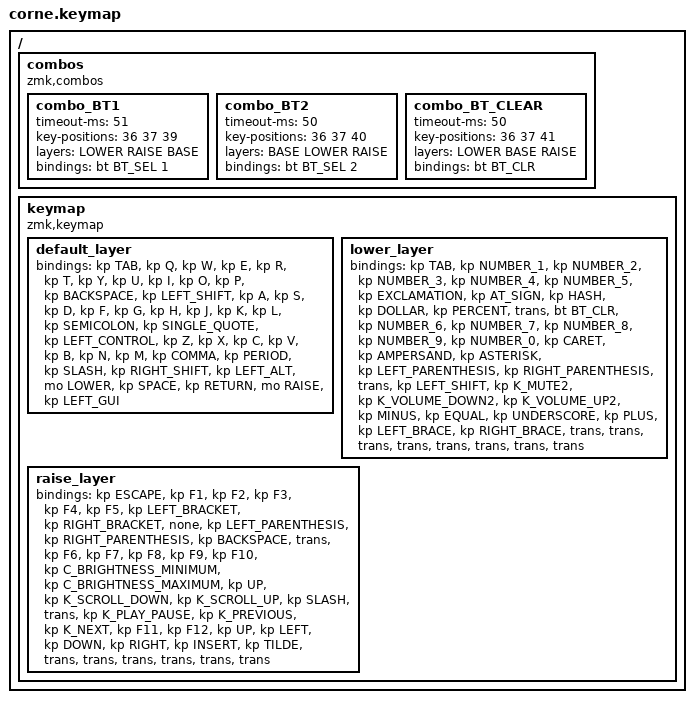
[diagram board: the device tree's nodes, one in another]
#include <behaviors.dtsi>
#include <dt-bindings/zmk/keys.h>
#include <dt-bindings/zmk/bt.h>

#define BASE 0
#define LOWER 1
#define RAISE 2

/ {
  combos {
    compatible = "zmk,combos";
    
    combo_BT1 {
      timeout-ms = <51>;
      key-positions = <36 37 39>;
      layers = <LOWER RAISE BASE>;
      bindings = <&bt BT_SEL 1>; 
    };
    
    combo_BT2 {
      timeout-ms = <50>;
      key-positions = <36 37 40>;
      layers = <BASE LOWER RAISE>;
      bindings = <&bt BT_SEL 2>; 
    };
    
    combo_BT_CLEAR {
      timeout-ms = <50>;
      key-positions = <36 37 41>;
      layers = <LOWER BASE RAISE>;
      bindings = <&bt BT_CLR>; 
    };
  };

  keymap {
    compatible = "zmk,keymap";

    default_layer {
      bindings = <
        &kp TAB &kp Q &kp W &kp E &kp R &kp T &kp Y &kp U &kp I &kp O &kp P &kp BACKSPACE &kp LEFT_SHIFT &kp A &kp S &kp D &kp F &kp G &kp H &kp J &kp K &kp L &kp SEMICOLON &kp SINGLE_QUOTE &kp LEFT_CONTROL &kp Z &kp X &kp C &kp V &kp B &kp N &kp M &kp COMMA &kp PERIOD &kp SLASH &kp RIGHT_SHIFT &kp LEFT_ALT &mo LOWER &kp SPACE &kp RETURN &mo RAISE &kp LEFT_GUI 
      >;
    };

    lower_layer {
      bindings = <
        &kp TAB &kp NUMBER_1 &kp NUMBER_2 &kp NUMBER_3 &kp NUMBER_4 &kp NUMBER_5 &kp EXCLAMATION &kp AT_SIGN &kp HASH &kp DOLLAR &kp PERCENT &trans &bt BT_CLR &kp NUMBER_6 &kp NUMBER_7 &kp NUMBER_8 &kp NUMBER_9 &kp NUMBER_0 &kp CARET &kp AMPERSAND &kp ASTERISK &kp LEFT_PARENTHESIS &kp RIGHT_PARENTHESIS &trans &kp LEFT_SHIFT &kp K_MUTE2 &kp K_VOLUME_DOWN2 &kp K_VOLUME_UP2 &kp MINUS &kp EQUAL &kp UNDERSCORE &kp PLUS &kp LEFT_BRACE &kp RIGHT_BRACE &trans &trans &trans &trans &trans &trans &trans &trans 
      >;
    };

    raise_layer {
      bindings = <
        &kp ESCAPE 
		&kp F1 
		&kp F2 
		&kp F3 
		&kp F4 
		&kp F5 
		&kp LEFT_BRACKET 
		&kp RIGHT_BRACKET 
		&none 
		&kp LEFT_PARENTHESIS 
		&kp RIGHT_PARENTHESIS 
		&kp BACKSPACE 
		&trans 
		&kp F6 
		&kp F7 
		&kp F8 
		&kp F9 
		&kp F10 
		&kp C_BRIGHTNESS_MINIMUM 
		&kp C_BRIGHTNESS_MAXIMUM 
		&kp UP 
		&kp K_SCROLL_DOWN 
		&kp K_SCROLL_UP 
		&kp SLASH 
		&trans 
		&kp K_PLAY_PAUSE 
		&kp K_PREVIOUS 
		&kp K_NEXT 
		&kp F11 
		&kp F12 
		&kp UP 
		&kp LEFT 
		&kp DOWN 
		&kp RIGHT 
		&kp INSERT 
		&kp TILDE 
		&trans 
		&trans 
		&trans 
		&trans 
		&trans 
		&trans 
      >;
    };

  };
};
